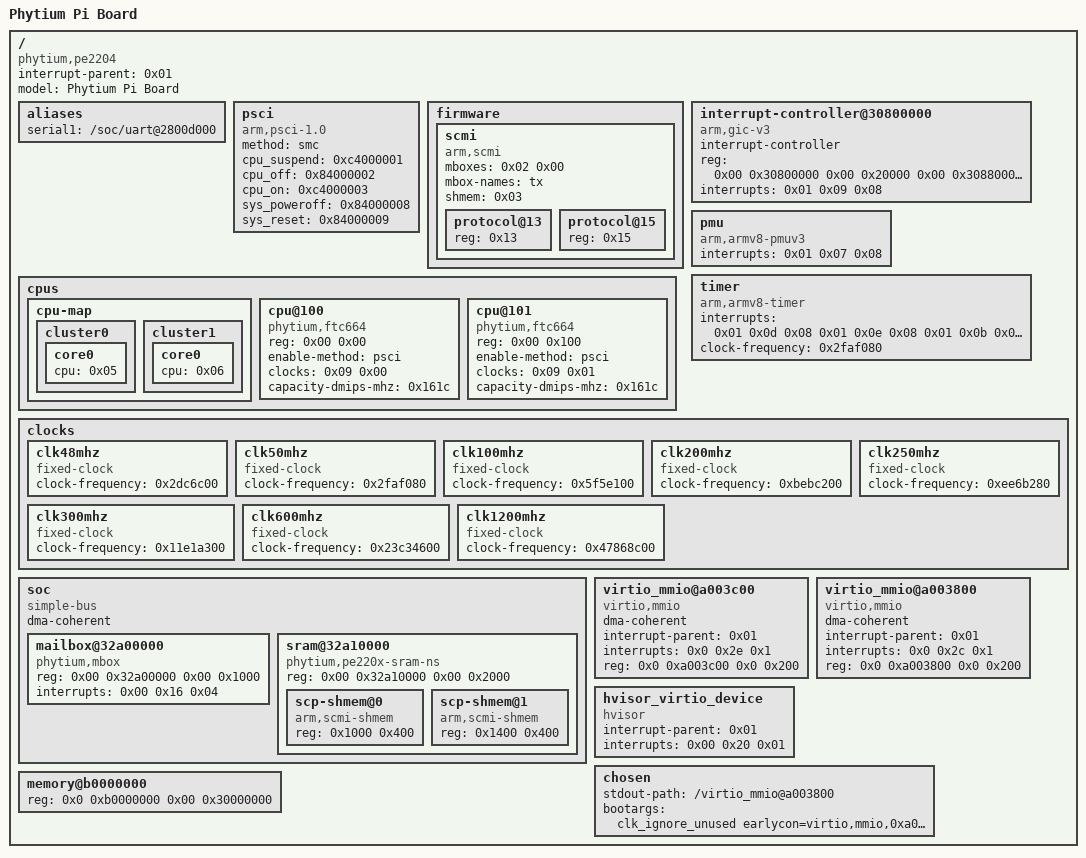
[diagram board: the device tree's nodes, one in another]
/dts-v1/;

/memreserve/	0x0000000080000000 0x0000000000010000;
/ {
	compatible = "phytium,pe2204";
	interrupt-parent = <0x01>;
	#address-cells = <0x02>;
	#size-cells = <0x02>;
	model = "Phytium Pi Board";

	aliases {
		serial1 = "/soc/uart@2800d000";
	};

	psci {
		compatible = "arm,psci-1.0";
		method = "smc";
		cpu_suspend = <0xc4000001>;
		cpu_off = <0x84000002>;
		cpu_on = <0xc4000003>;
		sys_poweroff = <0x84000008>;
		sys_reset = <0x84000009>;
	};

	firmware {

		scmi {
			compatible = "arm,scmi";
			mboxes = <0x02 0x00>;
			mbox-names = "tx";
			shmem = <0x03>;
			#address-cells = <0x01>;
			#size-cells = <0x00>;
			phandle = <0x18>;

			protocol@13 {
				reg = <0x13>;
				#clock-cells = <0x01>;
				phandle = <0x09>;
			};

			protocol@15 {
				reg = <0x15>;
				#thermal-sensor-cells = <0x01>;
				phandle = <0x04>;
			};
		};

		// optee {
		// 	compatible = "linaro,optee-tz";
		// 	method = "smc";
		// };
	};

	cpus {
		#address-cells = <0x02>;
		#size-cells = <0x00>;
		phandle = <0x19>;  

		cpu-map {

			cluster0 {

				core0 {
					cpu = <0x05>;
				};
			};

			cluster1 {

				core0 {
					cpu = <0x06>;
				};
			};

			// cluster2 {

			// 	core0 {
			// 		cpu = <0x07>;
			// 	};

			// 	core1 {
			// 		cpu = <0x08>;
			// 	};
			// };


		};

		// cpu@0 {
		// 	device_type = "cpu";
		// 	compatible = "phytium,ftc310\0arm,armv8";
		// 	reg = <0x00 0x200>;
		// 	enable-method = "psci";
		// 	clocks = <0x09 0x02>;
		// 	capacity-dmips-mhz = <0xb22>;
		// 	phandle = <0x07>;
		// };

		// cpu@1 {
		// 	device_type = "cpu";
		// 	compatible = "phytium,ftc310\0arm,armv8";
		// 	reg = <0x00 0x201>;
		// 	enable-method = "psci";
		// 	clocks = <0x09 0x02>;
		// 	capacity-dmips-mhz = <0xb22>;
		// 	phandle = <0x08>;
		// };

		cpu@100 {
			device_type = "cpu";
			compatible = "phytium,ftc664\0arm,armv8";
			reg = <0x00 0x00>;
			enable-method = "psci";
			clocks = <0x09 0x00>;
			capacity-dmips-mhz = <0x161c>;
			phandle = <0x05>;
		};

		cpu@101 {
			device_type = "cpu";
			compatible = "phytium,ftc664\0arm,armv8";
			reg = <0x00 0x100>;
			enable-method = "psci";
			clocks = <0x09 0x01>;
			capacity-dmips-mhz = <0x161c>;
			phandle = <0x06>;
		};
	};
	

	
	interrupt-controller@30800000 {
		compatible = "arm,gic-v3";
		#interrupt-cells = <0x03>;
		#address-cells = <0x02>;
		#size-cells = <0x02>;
		ranges;
		interrupt-controller;
		reg = <0x00 0x30800000 0x00 0x20000 0x00 0x30880000 0x00 0x80000>; 
		// reg = <0x00 0x30800000 0x00 0x20000 0x00 0x30880000 0x00 0x80000 0x00 0x30840000 0x00 0x10000 0x00 0x30850000 0x00 0x10000 0x00 0x30860000 0x00 0x10000>;
		interrupts = <0x01 0x09 0x08>;
		phandle = <0x01>;

		// gic-its@30820000 {
		// 	compatible = "arm,gic-v3-its";
		// 	msi-controller;
		// 	reg = <0x00 0x30820000 0x00 0x20000>;
		// 	phandle = <0x0f>;
		// };
	};

	pmu {
		compatible = "arm,armv8-pmuv3";
		interrupts = <0x01 0x07 0x08>;
	};
	timer {
		compatible = "arm,armv8-timer";
		interrupts = <0x01 0x0d 0x08 0x01 0x0e 0x08 0x01 0x0b 0x08 0x01 0x0a 0x08>;
		clock-frequency = <0x2faf080>;
	};


	clocks {
		#address-cells = <0x02>;
		#size-cells = <0x02>;
		ranges;

		clk48mhz {
			compatible = "fixed-clock";
			#clock-cells = <0x00>;
			clock-frequency = <0x2dc6c00>;
			phandle = <0x13>;
		};

		clk50mhz {
			compatible = "fixed-clock";
			#clock-cells = <0x00>;
			clock-frequency = <0x2faf080>;
			phandle = <0x0d>;
		};

		clk100mhz {
			compatible = "fixed-clock";
			#clock-cells = <0x00>;
			clock-frequency = <0x5f5e100>;
			phandle = <0x0c>;
		};

		clk200mhz {
			compatible = "fixed-clock";
			#clock-cells = <0x00>;
			clock-frequency = <0xbebc200>;
			phandle = <0x11>;
		};

		clk250mhz {
			compatible = "fixed-clock";
			#clock-cells = <0x00>;
			clock-frequency = <0xee6b280>;
			phandle = <0x12>;
		};

		clk300mhz {
			compatible = "fixed-clock";
			#clock-cells = <0x00>;
			clock-frequency = <0x11e1a300>;
			phandle = <0x0b>;
		};

		clk600mhz {
			compatible = "fixed-clock";
			#clock-cells = <0x00>;
			clock-frequency = <0x23c34600>;
			phandle = <0x0e>;
		};

		clk1200mhz {
			compatible = "fixed-clock";
			#clock-cells = <0x00>;
			clock-frequency = <0x47868c00>;
			phandle = <0x0a>;
		};
	};


	soc {
		compatible = "simple-bus";
		#address-cells = <0x02>;
		#size-cells = <0x02>;
		dma-coherent;
		ranges;
		phandle = <0x1a>;
		// mmc@28000000 {
		// 	compatible = "phytium,mci";
		// 	reg = <0x00 0x28000000 0x00 0x1000>;
		// 	interrupts = <0x00 0x48 0x04>;
		// 	clocks = <0x0a>;
		// 	clock-names = "phytium_mci_clk";
		// 	status = "okay";
		// 	bus-width = <0x04>;
		// 	max-frequency = <0x2faf080>;
		// 	cap-sdio-irq;
		// 	cap-sd-highspeed;
		// 	no-mmc;
		// 	phandle = <0x1b>;
		// };

		// mmc@28001000 {
		// 	compatible = "phytium,mci";
		// 	reg = <0x00 0x28001000 0x00 0x1000>;
		// 	interrupts = <0x00 0x49 0x04>;
		// 	clocks = <0x0a>;
		// 	clock-names = "phytium_mci_clk";
		// 	status = "okay";
		// 	bus-width = <0x04>;
		// 	max-frequency = <0x2faf080>;
		// 	#sd-uhs-sdr25;
		// 	#sd-uhs-sdr50;
		// 	cap-sdio-irq;
		// 	cap-sd-highspeed;
		// 	no-mmc;
		// 	no-sd;
		// 	non-removable;
		// 	phandle = <0x1c>;
		// };
		// uart@2800d000 {
		// 	compatible = "arm,pl011\0arm,primecell";
		// 	reg = <0x00 0x2800d000 0x00 0x1000>;
		// 	interrupts = <0x00 0x54 0x04>;
		// 	clocks = <0x0c 0x0c>;
		// 	clock-names = "uartclk\0apb_pclk";
		// 	status = "okay";
		// 	phandle = <0x22>;
		// };
		mailbox@32a00000 {
			compatible = "phytium,mbox";
			reg = <0x00 0x32a00000 0x00 0x1000>;
			interrupts = <0x00 0x16 0x04>;
			#mbox-cells = <0x01>;
			phandle = <0x02>;
		};
		
		sram@32a10000 {
			compatible = "phytium,pe220x-sram-ns\0mmio-sram";
			reg = <0x00 0x32a10000 0x00 0x2000>;
			#address-cells = <0x01>;
			#size-cells = <0x01>;
			ranges = <0x00 0x00 0x32a10000 0x2000>;
			phandle = <0x67>;

			scp-shmem@0 {
				compatible = "arm,scmi-shmem";
				reg = <0x1000 0x400>;
				phandle = <0x68>;
			};

			scp-shmem@1 {
				compatible = "arm,scmi-shmem";
				reg = <0x1400 0x400>;
				phandle = <0x03>;
			};
		};
		// i2c@28026000 {
		// 	compatible = "phytium,i2c";
		// 	reg = <0x00 0x28026000 0x00 0x1000>;
		// 	interrupts = <0x00 0x65 0x04>;
		// 	clocks = <0x0d>;
		// 	#address-cells = <0x01>;
		// 	#size-cells = <0x00>;
		// 	status = "okay";
		// 	phandle = <0x7a>;

		// 	rtc@68 {
		// 		compatible = "dallas,ds1339";
		// 		reg = <0x68>;
		// 	};
		// };

	};

	// virtio blk
	virtio_mmio@a003c00 {
		dma-coherent;
		interrupt-parent = <0x01>;
		interrupts = <0x0 0x2e 0x1>;
		reg = <0x0 0xa003c00 0x0 0x200>;
		compatible = "virtio,mmio";
	};
	//virtio serial
	virtio_mmio@a003800 {
		dma-coherent;
		interrupt-parent = <0x01>;
		interrupts = <0x0 0x2c 0x1>;
		reg = <0x0 0xa003800 0x0 0x200>;
		compatible = "virtio,mmio";
	};
	hvisor_virtio_device {
		compatible = "hvisor";
		interrupt-parent = <0x01>;
		interrupts = <0x00 0x20 0x01>;
	};


	chosen {

		stdout-path = "/virtio_mmio@a003800";
		bootargs = "clk_ignore_unused earlycon=virtio,mmio,0xa003800 console=hvc0 root=/dev/vda rootwait rw init=/bin/sh";
		// stdout-path = "serial1:115200n8";
		// bootargs = "clk_ignore_unused console=ttyAMA1,115200 earlycon=pl011,0x2800d000,115200 root=/dev/vda rw rootwait init=/bin/sh";

	};


	memory@b0000000 {
		device_type = "memory";
		reg = <0x0 0xb0000000 0x00 0x30000000>;
	};

	__symbols__ {
		scmi = "/firmware/scmi";
		scmi_dvfs = "/firmware/scmi/protocol@13";
		scmi_sensors0 = "/firmware/scmi/protocol@15";
		cpu = "/cpus";
		cpu_l0 = "/cpus/cpu@0";
		cpu_l1 = "/cpus/cpu@1";
		cpu_b0 = "/cpus/cpu@100";
		cpu_b1 = "/cpus/cpu@101";
		gic = "/interrupt-controller@30800000";
		// its = "/interrupt-controller@30800000/gic-its@30820000";
		sysclk_48mhz = "/clocks/clk48mhz";
		sysclk_50mhz = "/clocks/clk50mhz";
		sysclk_100mhz = "/clocks/clk100mhz";
		sysclk_200mhz = "/clocks/clk200mhz";
		sysclk_250mhz = "/clocks/clk250mhz";
		sysclk_300mhz = "/clocks/clk300mhz";
		sysclk_600mhz = "/clocks/clk600mhz";
		sysclk_1200mhz = "/clocks/clk1200mhz";
		soc = "/soc";
		// mmc0 = "/soc/mmc@28000000";
		// mmc1 = "/soc/mmc@28001000";
		// uart1 = "/soc/uart@2800d000";
		mbox = "/soc/mailbox@32a00000";
		sram = "/soc/sram@32a10000";
		cpu_scp_lpri = "/soc/sram@32a10000/scp-shmem@0";
		cpu_scp_hpri = "/soc/sram@32a10000/scp-shmem@1";
		// mio9 = "/soc/i2c@28026000";
	};
};
